# CALC3_MMR_ICONT register map
Vendor: Texas Instruments
Peripheral module from a debugger description file (folder DRA72x).
Registers are 32-bit, access per field, reset 0x0 unless marked. A register's access mark holds for its fields unless they carry their own. Offsets are as the file gives them; lines under a group give offsets from that group; [hi:lo] are bit positions; {n}, {i} and the like mark numbered series; 'fields as' and 'values as' point back to an identical list; <NAME> marks a mode.

## CALC3_MMR_ICONT
0x00 CALC_PID ro reset not defined — CALC3 PID register
  [31:0] PID — PID of CALC3
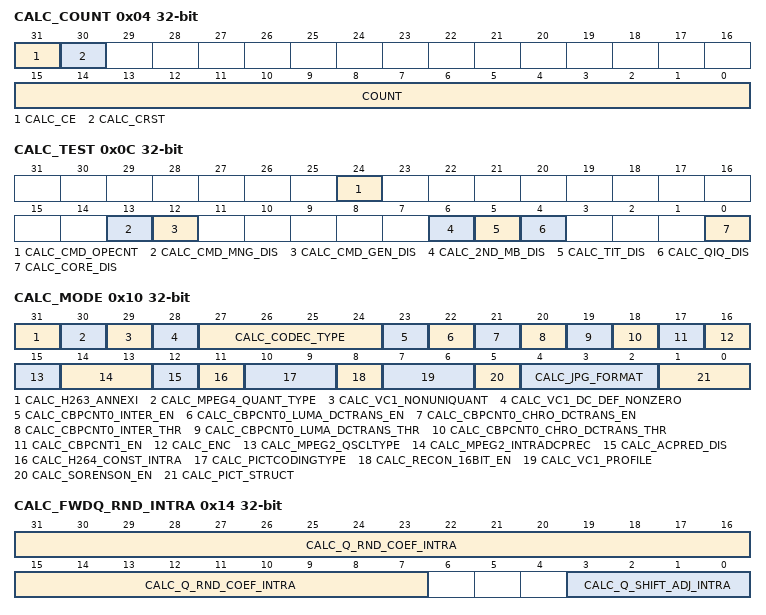
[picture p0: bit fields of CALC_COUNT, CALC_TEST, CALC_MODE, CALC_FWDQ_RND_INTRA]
0x04 CALC_COUNT — CALC3 cycle counter register
  [31] CALC_CE rw — Cycle counter enable [1]: Active [0]: Not active
  [30] CALC_CRST wo — Counter reset [1]: Reset counter [0]: No effect
  [15:0] COUNT ro — Cycle counter 16-bit counter Cycle counter is increasing during CALC_EN = 1 in CALC_CTRL. It reflects the counter value.
0x08 CALC_CTRL — CALC3 control register
  [0] CALC_EN rw — CALC3 module status and start bit Write [0]: Ignored Write [1]: Start CALC3 module. Read [0]: Idle Read [1]: Busy
0x0C CALC_TEST — CALC3 test register It is only for debug purpose.
  [24] CALC_CMD_OPECNT ro — MB counter register for MBAFF mode For H.264 MBAFF, this status bit is used for CALC3 core and command wrapper.
  [13] CALC_CMD_MNG_DIS rw — CALC3 command wrapper function of data management (that is, neighboring pixel copying) disable flag. [0]: Command wrapper's data management enable. [1]: Command wrapper's data management disable.
  [12] CALC_CMD_GEN_DIS rw — CALC3 command wrapper function of CALC3 core specific command generation disable flag. [0]: Command wrapper's its generation function enable. [1]: Command wrapper's its generation function disable.
  [6] CALC_2ND_MB_DIS rw — CALC3 2nd Mb disable flag ( it is effective only for MBAFF ) [1]: 2nd Mb operation for MBAFF is disable for CALC3 core and command wrapper [0]: 2nd Mb operation for MBAFF is enable for CALC3 core and command wrapper
  [5] CALC_TIT_DIS rw — CALC3 transform function disable flag [1]: Transform function is skipped in CALC3 core. [0]: Transform function is enabled in CALC3 core.
  [4] CALC_QIQ_DIS rw — CALC3 QIQ function disable flag [1]: QIQ function is skipped in CALC3 core. [0]: QIQ function is enabled in CALC3 core.
  [0] CALC_CORE_DIS rw — CALC3 core disable flag. [0]: CALC core enable [1]: CALC core disable
0x10 CALC_MODE rw — CALC3 mode select register
  [31] CALC_H263_ANNEXI — In H.264[0] : Intra_8x8 Pre-Filter is active. . [1] : Intra_8x8 Pre_filter is disabled. . H.263 AnnexI mode set flag . It is effective for H.263 decode only. . [0] : H263 Annex I configuration disable for CALC3 core . [1] : H263 Annex I configuration enable for CALC3 core .
  [30] CALC_MPEG4_QUANT_TYPE — MPEG-4 QuantType set flagIt is effective for MPEG-4 only. . [0]: QuantType = 0 . [1]: QuantType = 1 . It is set for the quantization manner, H.263 like (quantType = 0) or MPEG like(quantType = 1). . Based on the current syntax, user must set it. .
  [29] CALC_VC1_NONUNIQUANT — VC-1 NonUniformQuantize set flagIt is effective for VC-1 only. . [0]: Uniform Quantize . [1]: NonUniform Quantize . It is set for the quantization manner, uniform or nonuniform for VC-1. . Based on the current syntax, user must set it. .
  [28] CALC_VC1_DC_DEF_NONZERO — VC-1 DcDefaultNonZero set flagIt is effective for VC-1 only. . [0]: DcDefault = 0 . [1]: DcDefault != 0 . It is set for the DC default value for the DC prediction for VC-1. . If (Simple or Main Profile && Ipicture && NoOverlap) . set to 1 . else . set to 0 .
  [27:24] CALC_CODEC_TYPE — Codec type set register[0]: JPEG . [1]: MPEG-1 . [2]: MPEG-2 . [3]: H.263 . [4]: MPEG-4 . [5]: VC-1 . [6]: H.264 . [7]: AVS1.0 . [8]: Real Video . [9]: On2Vp6 . [10]: On2Vp7 . [11-15]: Reserved . For MPEG-4 and shortVideoHeader = 1, set H.263 mode. .
  [23] CALC_CBPCNT0_INTER_EN — CBPControl #0 enable flag for Inter Block[0]: Disable. . [1]: Enable. . It is effective for encode only. . For an 8 × 8 block (without DcTransform) and its block of inter, if all the nonzero coeffs among quantized 64 coeffs are less than one in abs domain and the number of the ones coeffs <= threshold_0, this corresponds CBP sets to zero, where threshold_0 = CALC_CBPCNT0_INTER_THR + 1. . Its threshold of threshold_0 can be set in the CALC_CBPCNT0_INTER_THR register. . Note that the abs one coefficients does not turn to zero in the residual data, the CBP is only controlled to zero. .
  [22] CALC_CBPCNT0_LUMA_DCTRANS_EN — CBPControl #0 enable flag for Luma DC Trans mode[0]: Disable. . [1]: Enable. . It is effective for encode and DC transform used in Luma 16 × 16 block. . When DcTransform is effective for Luma and this flag = 1, if all the non-zero coeffs among quantized 60 AC coeffs (w/o 4DC coeffs) in an 8 × 8 Luma block are one in abs domain and the number of ones coeffs is less than threshold_1, this corresponded CBP sets to zero, where threshold_1 = CALC_CBPCNT0_LUMA_DCTRANS_THR + 1. . Its threshold of threshold_1 can be set in the CALC_CBPCNT0_LUMA_DCTRANS_THR register. . Note that the abs one coefficients are not turns to zero in the residual data, the CBP is only controlled to zero. .
  [21] CALC_CBPCNT0_CHRO_DCTRANS_EN — CBPControl #0 enable flag for Chroma DC Trans mode[0]: Disable. . [1]: Enable. . It is effective for enc and DC transform used in Cb and Cr blocks. . When DcTransform is effective for Cb/Cr and this flag = 1, if all the non-zero coeffs among quantized 60 AC coeffs (w/o 4DC coeffs) in the 8x8 block are one in abs domain and the number of ones coeffs is less than threshold_2, this corresponded CBP sets to zero, where threshold_2 = CALC_CBPCNT0_CHRO_DCTRANS_THR + 1. . Its threshold of threshold_2 is set in the CALC_CBPCNT0_CHRO_DCTRANS_THR register. . Note that the abs one coefficients are not turns to zero in the residual data, the CBP is only controlled to zero. .
  [20] CALC_CBPCNT0_INTER_THR — # of abs ones coeffs threshold for CALC_CBPCNT0_INTER_ENIt is effective for CALC_CBPCNT0_INTER_EN = 1 . [0]: threshold_0 = 1 . [1]: threshold_0 = 2 .
  [19] CALC_CBPCNT0_LUMA_DCTRANS_THR — # of abs ones coeffs threshold for CALC_CBPCNT0_LUMA_DCTRANS_ENIt is effective for CALC_CBPCNT0_LUMA_DCTRANS_EN = 1 . [0]: threshold_1 = 1 . [1]: threshold_1 = 2 .
  [18] CALC_CBPCNT0_CHRO_DCTRANS_THR — # of abs ones coeffs threshold for CALC_CBPCNT0_CHRO_DCTRANS_ENIt is effective for CALC_CBPCNT0_CHRO_DCTRANS_EN = 1 . [0]: threshold_2 = 1 . [1]: threshold_2 = 2 .
  [17] CALC_CBPCNT1_EN — CBP Control #1 enable flag[0]: OFF . [1]: ON . It is effective for encode. . If all the inverse transformed coefficients are zeros in the transformed size, the corresponded CBP controls to zero. . Note that the abs one coefficients are not turns to zero in the residual data, the CBP is only controlled to zero. .
  [16] CALC_ENC — Enc or Dec mode flag[0]: Dec . [1]: Enc . Note that a part of codecs is supported only for dec. . RealVideo, VP6/7, H.263 AnnexI mode are supported only for dec. . Enc mode is reserved for them. .
  [15] CALC_MPEG2_QSCLTYPE — q_scale_type of MPEG-2 set register for command wrapper.It is effective for MPEG-2. . [0]: q_scale_type = 0 . [1]: q_scale_type = 1 .
  [14:13] CALC_MPEG2_INTRADCPREC — intra_dc_precision of MPEG-2 set register for command wrapper.It is effective for MPEG-1 and MPEG-2. . [0]: intra_dc_precision = 0 . [1]: intra_dc_precision = 1 . [2]: intra_dc_precision = 2 . [3]: intra_dc_precision = 3 . For MPEG-1, it shall be set to zero. .
  [12] CALC_ACPRED_DIS — AC prediction disable flag for command wrapper.It is effective for MPEG-4 and VC-1 enc. . [0]: AC prediction estimation enable for enc . [1]: AC prediction estimation disable for enc . Note that H.263 AnnexI enc not support. .
  [11] CALC_H264_CONST_INTRA — Constraint intra set of H.264 flag for command wrapper.It is effective for H.264. . [0]: Non constraint intra . [1]: constraint intra .
  [10:9] CALC_PICTCODINGTYPE — Picture coding type set register for command wrapper[0]: I Picture . [1]: P Picture . [2]: B Picture . [3]: Reserved . It is effective for VC-1 and RealVideo. . For VC-1, it defines DcPrediction manner. . For RV8, it defines quantization parameter for the inverse quantization of Dc Transformed coefficient. .
  [8] CALC_RECON_16BIT_EN — Reconstruct format flag[0]: 8-bit mode . [1]: 16-bit mode . For VC-1 application, it must always be set to 1. . Even for an inter block, CALC3 outputs the reconst data in 16-bit format for its flag of 1. . We assume that the 8-bit clipping would be done in ILF3. . For other codecs, it shall be set to zero. .
  [7:6] CALC_VC1_PROFILE — VC-1 Profile register for command wrapper[0]: Simple . [1]: Main . [2]: Advanced . [3]: Reserved . It is effective for VC-1, since DcPrediction manner is defined by it. .
  [5] CALC_SORENSON_EN — Sorenson Spark setting register.When CALC_CODEC_TYPE = 3 (H.263) and this flag = 1, then, it becomes Sorenson Spark mode. . For this flag = 1, CALC_H263_ANNEXI must be set to zero. .
  [4:2] CALC_JPG_FORMAT — JPEG color mode setting register.It is effective for JPEG. . [0]: 4:4:4 (1 MCU mode) . [1]: 4:4:4 (2 MCU mode) . [2]: 4:2:2 (H0 = 2 V0 = 1) . [3]: 4:2:2 (H0 = 1 V0 = 2) . [4]: 4:2:0 . [5]: Reserved . [6]: 4:0:0 . [7]: Reserved .
  [1:0] CALC_PICT_STRUCT — Picture Structure setting register[0]: Frame structure . [1]: Field structure . [2]: MBAFF (MbPair sequence) . [3]: Reserved . Field structure mode shall be set for interlace field picture. . MBAFF mode shall be set for H.264 MBAFF picture. . Frame structure mode shall be set for others. . Note that CALC3 handles top and bottom MBs simultaneously with one start pulse for AFF mode. . With one start pulse, CALC3 handles only one MB except for MBAFF mode. .
0x14 CALC_FWDQ_RND_INTRA — CALC3 forward quantization's rounding coefficients and shift offsets for intra MB
  [31:7] CALC_Q_RND_COEF_INTRA rw — Forward quantization's rounding coefficients for intra MB. Hence, for intra MB and fwdQ, Round Coefficient AC[0] = this bit field by command wrapper (Signed 25-bit).
  [3:0] CALC_Q_SHIFT_ADJ_INTRA rw — It can be applicable for weight matrix used codecs' encoding. If user would like to apply a non-default intra weight matrix and its element is less than that of default value, then the user shall set it. Otherwise, zero shall be set. Forward Q shift adjustment for inter macroblock. (Signed 4bits, valid for MPEG-1/-2, MPEG-4 quantType=1, H.264, = q_shift_adj[0] for command wrapper).
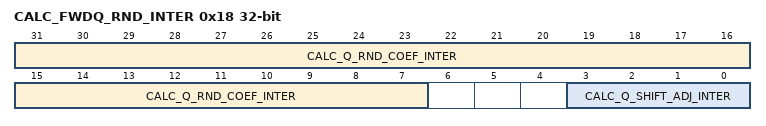
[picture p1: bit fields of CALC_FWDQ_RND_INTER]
0x18 CALC_FWDQ_RND_INTER — CALC3 forward quantization's rounding coefficients and shift offsets for inter MB
  [31:7] CALC_Q_RND_COEF_INTER rw — Forward quantization's rounding coefficients for inter MB. Hence, for inter MB and fwdQ, Round Coefficient AC[0] = this bit field by command wrapper (Table 22/23) (Signed 25-bit).
  [3:0] CALC_Q_SHIFT_ADJ_INTER rw — It can be applicable for weight matrix used codecs' encoding. If user would like to apply a non-default inter weight matrix and its element is less than that of default value, then the user shall set it. Otherwise, zero shall be set. Forward Q shift adjustment for inter macroblock. (Signed 4bits, valid for MPEG-1/-2, MPEG-4 quantType=1, H.264, = q_shift_adj[1] for command wrapper).
0x20 CALC_FWDQ_RND_INTRA_DC — Round offset value setting for fwd Q, intra and DC coefficient.
  [31:7] CALC_Q_RND_COEF_INTRA_DC rw — Forward quantization's rounding coefficients for intra MB and its DC coefficients. Hence, for intra MB, fwdQ and DC coefficients, FwdQ uses it as its rounding coefficient. Fwd Round Coefficient DC[0] = this bit field by command wrapper(Table. 21/22)(Signed 25-bit).
0x24 CALC_FWDQ_RND_INTER_DC — Round offset value setting for fwd Q, inter and DC coefficient.
  [31:7] CALC_Q_RND_COEF_INTER_DC rw — Forward quantization's rounding coefficients for inter MB and its DC coefficients. Hence, for inter MB, fwdQ and DC coefficients, FwdQ uses it as its rounding coefficient. Round Coefficient DC[0] = this bit field (Table. 21/22) (Signed 25-bit).
